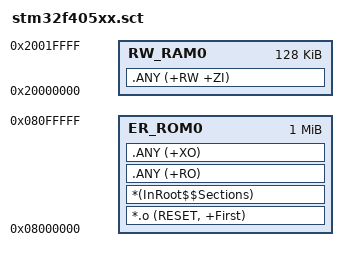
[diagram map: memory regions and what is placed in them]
LR_ROM0 0x08000000 0x00100000 {

  ER_ROM0 0x08000000 0x00100000 {
   *.o (RESET, +First)
   *(InRoot$$Sections)
   .ANY (+RO)
   .ANY (+XO)
  }

  RW_RAM0 0x20000000 0x00020000 {
   .ANY (+RW +ZI)
  }
}
